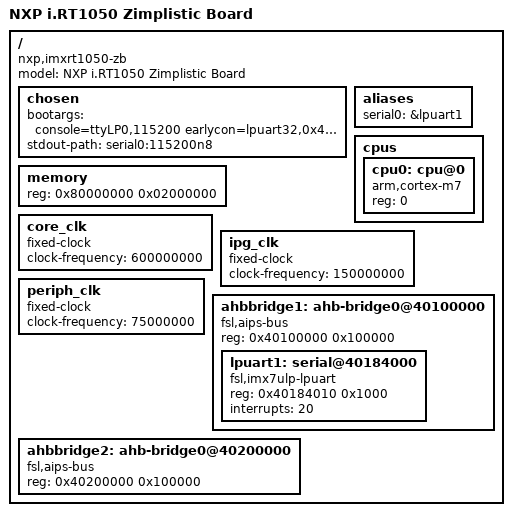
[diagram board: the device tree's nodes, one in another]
/*
 * Copyright 2016 Freescale Semiconductor, Inc.
 *
 * This program is free software; you can redistribute it and/or modify
 * it under the terms of the GNU General Public License version 2 as
 * published by the Free Software Foundation.
 */

/dts-v1/;

/ {
	model = "NXP i.RT1050 Zimplistic Board";
	compatible = "nxp,imxrt1050-zb", "nxp,imxrt1050", "Generic DT based system";

	#address-cells = <1>;
	#size-cells = <1>;

	chosen {
		bootargs = "console=ttyLP0,115200 earlycon=lpuart32,0x402D0010,115200";
		stdout-path = "serial0:115200n8";
	};

	aliases {
		serial0 = &lpuart1;
	};

	cpus {
		#address-cells = <1>;
		#size-cells = <0>;

		cpu0: cpu@0 {
			compatible = "arm,cortex-m7";
			device_type = "cpu";
			reg = <0>;
		};
	};

	memory {
		device_type = "memory";
		reg = <0x80000000 0x02000000>;
	};

	core_clk: core_clk {
		compatible = "fixed-clock";
		#clock-cells = <0>;
		clock-frequency = <600000000>;
	};

	ipg_clk: ipg_clk {
		compatible = "fixed-clock";
		#clock-cells = <0>;
		clock-frequency = <150000000>;
	};

	periph_clk: periph_clk {
		compatible = "fixed-clock";
		#clock-cells = <0>;
		clock-frequency = <75000000>;
	};

	ahbbridge1: ahb-bridge0@40100000 {
		compatible = "fsl,aips-bus", "simple-bus";
		#address-cells = <1>;
		#size-cells = <1>;
		reg = <0x40100000 0x100000>;
		ranges;

		lpuart1: serial@40184000 {
			compatible = "fsl,imx7ulp-lpuart";
			reg = <0x40184010 0x1000>;
			interrupts = <20>;
			status = "disabled";
		};
	};

	ahbbridge2: ahb-bridge0@40200000 {
		compatible = "fsl,aips-bus", "simple-bus";
		#address-cells = <1>;
		#size-cells = <1>;
		reg = <0x40200000 0x100000>;
		ranges;
	};
};

&lpuart1 {
	status = "okay";
};
